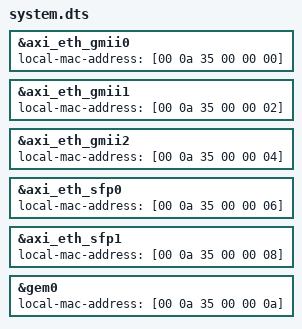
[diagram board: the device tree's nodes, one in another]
/*
 * CAUTION: This file is automatically generated by Xilinx.
 * Version: XSCT 2019.1
 * Today is: Sat Aug 24 05:30:11 2019
 */


&axi_eth_gmii0 {
	local-mac-address = [00 0a 35 00 00 00];
};
&axi_eth_gmii1 {
	local-mac-address = [00 0a 35 00 00 02];
};
&axi_eth_gmii2 {
	local-mac-address = [00 0a 35 00 00 04];
};
&axi_eth_sfp0 {
	local-mac-address = [00 0a 35 00 00 06];
};
&axi_eth_sfp1 {
	local-mac-address = [00 0a 35 00 00 08];
};
&gem0 {
	local-mac-address = [00 0a 35 00 00 0a];
};
